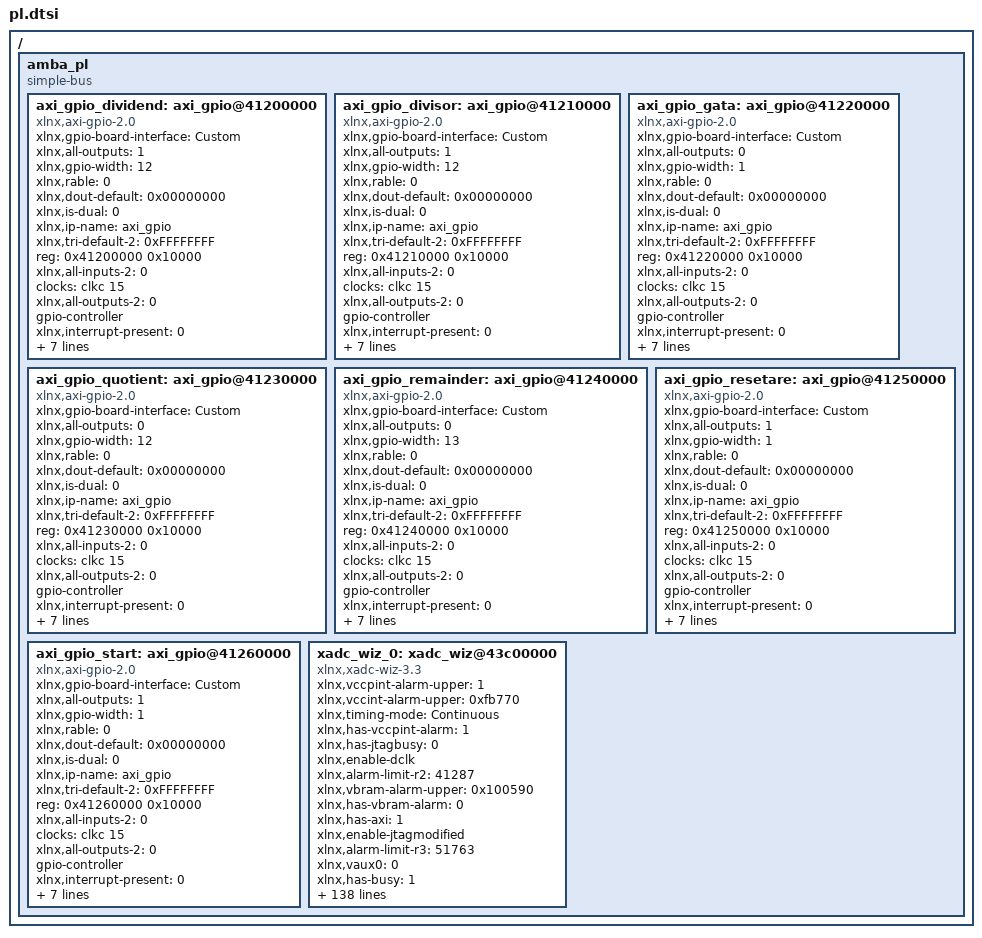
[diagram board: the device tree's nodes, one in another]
/ {
	amba_pl: amba_pl {
		ranges;
		compatible = "simple-bus";
		#address-cells = <1>;
		#size-cells = <1>;
		axi_gpio_dividend: axi_gpio@41200000 {
			xlnx,gpio-board-interface = "Custom";
			compatible = "xlnx,axi-gpio-2.0" , "xlnx,xps-gpio-1.00.a";
			xlnx,all-outputs = <1>;
			#gpio-cells = <2>;
			xlnx,gpio-width = <12>;
			xlnx,rable = <0>;
			xlnx,dout-default = <0x00000000>;
			xlnx,is-dual = <0>;
			xlnx,ip-name = "axi_gpio";
			xlnx,tri-default-2 = <0xFFFFFFFF>;
			reg = <0x41200000 0x10000>;
			xlnx,all-inputs-2 = <0>;
			clocks = <&clkc 15>;
			xlnx,all-outputs-2 = <0>;
			gpio-controller;
			xlnx,interrupt-present = <0>;
			xlnx,gpio2-board-interface = "Custom";
			xlnx,edk-iptype = "PERIPHERAL";
			xlnx,dout-default-2 = <0x00000000>;
			xlnx,gpio2-width = <32>;
			status = "okay";
			clock-names = "s_axi_aclk";
			xlnx,tri-default = <0xFFFFFFFF>;
			xlnx,name = "axi_gpio_dividend";
			xlnx,all-inputs = <0>;
		};
		axi_gpio_divisor: axi_gpio@41210000 {
			xlnx,gpio-board-interface = "Custom";
			compatible = "xlnx,axi-gpio-2.0" , "xlnx,xps-gpio-1.00.a";
			xlnx,all-outputs = <1>;
			#gpio-cells = <2>;
			xlnx,gpio-width = <12>;
			xlnx,rable = <0>;
			xlnx,dout-default = <0x00000000>;
			xlnx,is-dual = <0>;
			xlnx,ip-name = "axi_gpio";
			xlnx,tri-default-2 = <0xFFFFFFFF>;
			reg = <0x41210000 0x10000>;
			xlnx,all-inputs-2 = <0>;
			clocks = <&clkc 15>;
			xlnx,all-outputs-2 = <0>;
			gpio-controller;
			xlnx,interrupt-present = <0>;
			xlnx,gpio2-board-interface = "Custom";
			xlnx,edk-iptype = "PERIPHERAL";
			xlnx,dout-default-2 = <0x00000000>;
			xlnx,gpio2-width = <32>;
			status = "okay";
			clock-names = "s_axi_aclk";
			xlnx,tri-default = <0xFFFFFFFF>;
			xlnx,name = "axi_gpio_divisor";
			xlnx,all-inputs = <0>;
		};
		axi_gpio_gata: axi_gpio@41220000 {
			xlnx,gpio-board-interface = "Custom";
			compatible = "xlnx,axi-gpio-2.0" , "xlnx,xps-gpio-1.00.a";
			xlnx,all-outputs = <0>;
			#gpio-cells = <2>;
			xlnx,gpio-width = <1>;
			xlnx,rable = <0>;
			xlnx,dout-default = <0x00000000>;
			xlnx,is-dual = <0>;
			xlnx,ip-name = "axi_gpio";
			xlnx,tri-default-2 = <0xFFFFFFFF>;
			reg = <0x41220000 0x10000>;
			xlnx,all-inputs-2 = <0>;
			clocks = <&clkc 15>;
			xlnx,all-outputs-2 = <0>;
			gpio-controller;
			xlnx,interrupt-present = <0>;
			xlnx,gpio2-board-interface = "Custom";
			xlnx,edk-iptype = "PERIPHERAL";
			xlnx,dout-default-2 = <0x00000000>;
			xlnx,gpio2-width = <32>;
			status = "okay";
			clock-names = "s_axi_aclk";
			xlnx,tri-default = <0xFFFFFFFF>;
			xlnx,name = "axi_gpio_gata";
			xlnx,all-inputs = <1>;
		};
		axi_gpio_quotient: axi_gpio@41230000 {
			xlnx,gpio-board-interface = "Custom";
			compatible = "xlnx,axi-gpio-2.0" , "xlnx,xps-gpio-1.00.a";
			xlnx,all-outputs = <0>;
			#gpio-cells = <2>;
			xlnx,gpio-width = <12>;
			xlnx,rable = <0>;
			xlnx,dout-default = <0x00000000>;
			xlnx,is-dual = <0>;
			xlnx,ip-name = "axi_gpio";
			xlnx,tri-default-2 = <0xFFFFFFFF>;
			reg = <0x41230000 0x10000>;
			xlnx,all-inputs-2 = <0>;
			clocks = <&clkc 15>;
			xlnx,all-outputs-2 = <0>;
			gpio-controller;
			xlnx,interrupt-present = <0>;
			xlnx,gpio2-board-interface = "Custom";
			xlnx,edk-iptype = "PERIPHERAL";
			xlnx,dout-default-2 = <0x00000000>;
			xlnx,gpio2-width = <32>;
			status = "okay";
			clock-names = "s_axi_aclk";
			xlnx,tri-default = <0xFFFFFFFF>;
			xlnx,name = "axi_gpio_quotient";
			xlnx,all-inputs = <1>;
		};
		axi_gpio_remainder: axi_gpio@41240000 {
			xlnx,gpio-board-interface = "Custom";
			compatible = "xlnx,axi-gpio-2.0" , "xlnx,xps-gpio-1.00.a";
			xlnx,all-outputs = <0>;
			#gpio-cells = <2>;
			xlnx,gpio-width = <13>;
			xlnx,rable = <0>;
			xlnx,dout-default = <0x00000000>;
			xlnx,is-dual = <0>;
			xlnx,ip-name = "axi_gpio";
			xlnx,tri-default-2 = <0xFFFFFFFF>;
			reg = <0x41240000 0x10000>;
			xlnx,all-inputs-2 = <0>;
			clocks = <&clkc 15>;
			xlnx,all-outputs-2 = <0>;
			gpio-controller;
			xlnx,interrupt-present = <0>;
			xlnx,gpio2-board-interface = "Custom";
			xlnx,edk-iptype = "PERIPHERAL";
			xlnx,dout-default-2 = <0x00000000>;
			xlnx,gpio2-width = <32>;
			status = "okay";
			clock-names = "s_axi_aclk";
			xlnx,tri-default = <0xFFFFFFFF>;
			xlnx,name = "axi_gpio_remainder";
			xlnx,all-inputs = <1>;
		};
		axi_gpio_resetare: axi_gpio@41250000 {
			xlnx,gpio-board-interface = "Custom";
			compatible = "xlnx,axi-gpio-2.0" , "xlnx,xps-gpio-1.00.a";
			xlnx,all-outputs = <1>;
			#gpio-cells = <2>;
			xlnx,gpio-width = <1>;
			xlnx,rable = <0>;
			xlnx,dout-default = <0x00000000>;
			xlnx,is-dual = <0>;
			xlnx,ip-name = "axi_gpio";
			xlnx,tri-default-2 = <0xFFFFFFFF>;
			reg = <0x41250000 0x10000>;
			xlnx,all-inputs-2 = <0>;
			clocks = <&clkc 15>;
			xlnx,all-outputs-2 = <0>;
			gpio-controller;
			xlnx,interrupt-present = <0>;
			xlnx,gpio2-board-interface = "Custom";
			xlnx,edk-iptype = "PERIPHERAL";
			xlnx,dout-default-2 = <0x00000000>;
			xlnx,gpio2-width = <32>;
			status = "okay";
			clock-names = "s_axi_aclk";
			xlnx,tri-default = <0xFFFFFFFF>;
			xlnx,name = "axi_gpio_resetare";
			xlnx,all-inputs = <0>;
		};
		axi_gpio_start: axi_gpio@41260000 {
			xlnx,gpio-board-interface = "Custom";
			compatible = "xlnx,axi-gpio-2.0" , "xlnx,xps-gpio-1.00.a";
			xlnx,all-outputs = <1>;
			#gpio-cells = <2>;
			xlnx,gpio-width = <1>;
			xlnx,rable = <0>;
			xlnx,dout-default = <0x00000000>;
			xlnx,is-dual = <0>;
			xlnx,ip-name = "axi_gpio";
			xlnx,tri-default-2 = <0xFFFFFFFF>;
			reg = <0x41260000 0x10000>;
			xlnx,all-inputs-2 = <0>;
			clocks = <&clkc 15>;
			xlnx,all-outputs-2 = <0>;
			gpio-controller;
			xlnx,interrupt-present = <0>;
			xlnx,gpio2-board-interface = "Custom";
			xlnx,edk-iptype = "PERIPHERAL";
			xlnx,dout-default-2 = <0x00000000>;
			xlnx,gpio2-width = <32>;
			status = "okay";
			clock-names = "s_axi_aclk";
			xlnx,tri-default = <0xFFFFFFFF>;
			xlnx,name = "axi_gpio_start";
			xlnx,all-inputs = <0>;
		};
		xadc_wiz_0: xadc_wiz@43c00000 {
			xlnx,vccpint-alarm-upper = <1>;
			xlnx,vccint-alarm-upper = <0xfb770>;
			xlnx,timing-mode = "Continuous";
			xlnx,has-vccpint-alarm = <1>;
			xlnx,has-jtagbusy = <0>;
			xlnx,enable-dclk;
			xlnx,alarm-limit-r2 = <41287>;
			xlnx,vbram-alarm-upper = <0x100590>;
			xlnx,has-vbram-alarm = <0>;
			xlnx,has-axi = <1>;
			xlnx,enable-jtagmodified;
			xlnx,alarm-limit-r3 = <51763>;
			xlnx,vaux0 = <0>;
			xlnx,has-busy = <1>;
			xlnx,alarm-limit-r4 = <43322>;
			xlnx,channel-enable-vccpaux;
			xlnx,vaux1 = <0>;
			xlnx,ot-alarm;
			xlnx,has-vccaux-alarm = <1>;
			xlnx,enable-channel;
			xlnx,alarm-limit-r5 = <21190>;
			xlnx,dclk-frequency = <100>;
			xlnx,vaux2 = <0>;
			xlnx,rable = <0>;
			xlnx,alarm-limit-r6 = <38229>;
			xlnx,vaux3 = <0>;
			xlnx,has-drp = <0>;
			xlnx,ip-name = "xadc_wiz";
			xlnx,alarm-limit-r7 = <44622>;
			xlnx,configuration-r0 = <0>;
			xlnx,vaux4 = <0>;
			xlnx,sim-file-rel-path = "./";
			xlnx,external-mux-channel = "VP_VN";
			reg = <0x43c00000 0x10000>;
			xlnx,alarm-limit-r8 = <22937>;
			xlnx,configuration-r1 = <8608>;
			xlnx,vccint-alarm;
			xlnx,vaux5 = <0>;
			xlnx,temperature-alarm-trigger = <85>;
			xlnx,has-jtaglocked = <0>;
			xlnx,alarm-limit-r9 = <20753>;
			xlnx,c-component-name = "design_1_xadc_wiz_0_0";
			xlnx,channel-enable-vccpint;
			xlnx,configuration-r2 = <1024>;
			xlnx,vaux6 = <1>;
			xlnx,channel-enable-vbram;
			xlnx,vaux7 = <1>;
			xlnx,vaux8 = <0>;
			xlnx,user-temp-alarm;
			xlnx,vaux9 = <0>;
			xlnx,vaux10 = <0>;
			xlnx,has-vn = <1>;
			xlnx,has-vccpaux-alarm = <1>;
			xlnx,acquisition-time = <4>;
			xlnx,vaux11 = <0>;
			xlnx,has-temp-bus = <0>;
			xlnx,xadc-starup-selection = "channel_sequencer";
			xlnx,vaux12 = <0>;
			xlnx,sim-file-sel = "Default";
			xlnx,has-vp = <1>;
			xlnx,channel-enable-vauxp14-vauxn14;
			xlnx,data-width = <32>;
			xlnx,enable-busy;
			xlnx,ip-type = <0x0>;
			xlnx,vaux13 = <0>;
			xlnx,temperature-alarm-ot-reset = <70>;
			xlnx,channel-enable-temperature;
			xlnx,vaux14 = <1>;
			xlnx,enable-convst;
			xlnx,channel-enable-vauxp15-vauxn15;
			xlnx,channel-enable-vp-vn;
			xlnx,vccpaux-alarm-lower = <0x1a17b0>;
			xlnx,vccaux-alarm-lower = <0x1ab3f0>;
			xlnx,vaux15 = <1>;
			compatible = "xlnx,xadc-wiz-3.3" , "xlnx,axi-xadc-1.00.a";
			xlnx,has-external-mux = <0>;
			xlnx,vccaux-alarm;
			xlnx,sampling-rate = <0x7fffffff>;
			xlnx,has-reset = <0>;
			xlnx,adc-conversion-rate = <1000>;
			xlnx,vccddro-alarm-lower = <0x124f80>;
			xlnx,has-user-temp-alarm = <1>;
			xlnx,enable-calibration-averaging;
			xlnx,has-ot-alarm = <1>;
			xlnx,has-convst = <0>;
			xlnx,enable-axi4stream;
			xlnx,single-channel-selection = "TEMPERATURE";
			xlnx,startup-channel-selection = "single_channel";
			xlnx,interface-selection = "Enable_AXI";
			xlnx,vccpaux-alarm-upper = <0x1b7740>;
			xlnx,vccaux-alarm-upper = <0x1cd6d0>;
			status = "okay";
			xlnx,sensor-offset-and-gain-calibration;
			xlnx,vccddro-alarm-upper = <0x1312d0>;
			xlnx,name = "xadc_wiz_0";
			xlnx,external-mux = "none";
			xlnx,enable-vccddro-alarm;
			xlnx,enable-eoc;
			xlnx,sim-file-name = "design";
			xlnx,enable-jtaglocked;
			xlnx,enable-vccpint-alarm;
			xlnx,channel-enable-vccddro;
			xlnx,temperature-alarm-reset = <60>;
			xlnx,addr-width = <32>;
			clocks = <&clkc 15>, <&clkc 15>;
			xlnx,alarm-limit-r10 = <21845>;
			xlnx,alarm-limit-r11 = <20753>;
			xlnx,alarm-limit-r12 = <39321>;
			xlnx,alarm-limit-r13 = <37355>;
			xlnx,edk-iptype = "PERIPHERAL";
			xlnx,sequencer-mode = "Continuous";
			xlnx,enable-jtagbusy;
			xlnx,alarm-limit-r14 = <27306>;
			xlnx,include-intr = <1>;
			xlnx,fifo-depth = <7>;
			xlnx,alarm-limit-r15 = <26214>;
			clock-names = "s_axi_aclk" , "s_axis_aclk";
			xlnx,has-eoc = <1>;
			xlnx,enable-vccpaux-alarm;
			xlnx,temperature-alarm-ot-trigger = <125>;
			xlnx,has-channel = <1>;
			xlnx,enable-eos;
			xlnx,channel-enable-vauxp7-vauxn7;
			xlnx,channel-enable-vccaux;
			xlnx,vccpint-alarm-lower = <0xe7ef0>;
			xlnx,vccint-alarm-lower = <0xecd10>;
			xlnx,has-dclk = <1>;
			xlnx,vbram-alarm-lower = <0xe7ef0>;
			xlnx,sequence-r0 = <20448>;
			xlnx,num-wave = <1>;
			xlnx,has-jtagmodified = <0>;
			xlnx,sequence-r1 = <49344>;
			xlnx,channel-enable-vauxp6-vauxn6;
			xlnx,channel-enable-vccint;
			xlnx,sequence-r2 = <0>;
			xlnx,has-vccint-alarm = <1>;
			xlnx,enable-drp;
			xlnx,channel-averaging = "None";
			xlnx,sequence-r3 = <0>;
			xlnx,has-axi4stream = <1>;
			xlnx,sequence-r4 = <0>;
			xlnx,sequence-r5 = <0>;
			xlnx,adc-offset-and-gain-calibration;
			xlnx,waveform-type = "CONSTANT";
			xlnx,sequence-r6 = <0>;
			xlnx,vccddro-volt = "1_2";
			xlnx,sequence-r7 = <0>;
			xlnx,has-vccddro-alarm = <1>;
			xlnx,has-eos = <1>;
			xlnx,has-convstclk = <0>;
			xlnx,alarm-limit-r0 = <46573>;
			xlnx,stimulus-freq = <1>;
			xlnx,single-channel-enable-calibration;
			xlnx,external-muxaddr-enable = <0>;
			xlnx,alarm-limit-r1 = <22500>;
		};
	};
};
